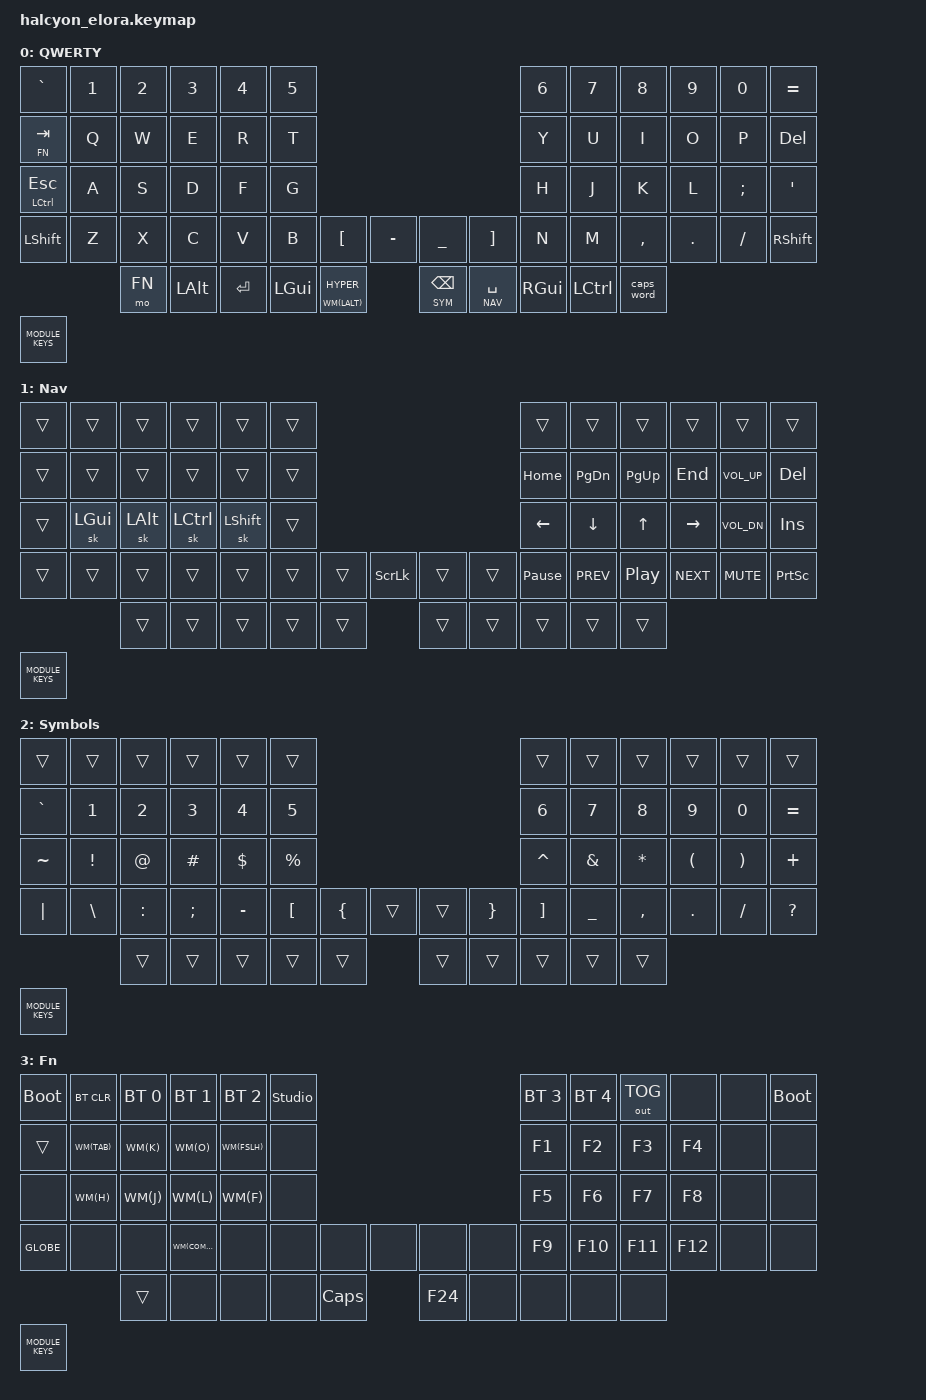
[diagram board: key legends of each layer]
/*
 * Halcyon Elora rev2 (wireless, dongle): Denis's keymap.
 *
 * Positions follow splitkb_halcyon_elora_hlc: rows 0–11, 12–23, 24–35,
 * 36–51 (with the four inner keys), thumbs 52–61, then the ten unused
 * Halcyon module positions 62–71.
 *
 * AeroSpace uses Ctrl+Alt as its modifier, so holding the Hyper thumb or
 * using the Fn window keys drives it; see ~/.nix/aerospace.nix.
 */

#include <behaviors.dtsi>
#include <dt-bindings/zmk/bt.h>
#include <dt-bindings/zmk/keys.h>
#include <dt-bindings/zmk/outputs.h>

#define BASE 0
#define NAV 1
#define SYM 2
#define FN 3

#define HYPER LS(LC(LA(LGUI)))
#define WM(key) LC(LA(key))

#define MODULE_KEYS &none &none &none &none &none &none &none &none &none &none

/* Tab/Fn, Space/Nav and Backspace/Sym take their hold as soon as another key goes down. */
&lt {
    flavor = "hold-preferred";
    tapping-term-ms = <175>;
    quick-tap-ms = <120>;
};

/* QMK's one-shot mods had no timeout; long enough to reach for the mouse. */
&sk {
    release-after-ms = <3000>;
};

/ {
    behaviors {
        /*
         * Esc/Ctrl only becomes Ctrl with a right-hand, thumb or neutral key
         * (Tab/Fn, [ and ]), matching QMK's chordal hold: a quick same-hand
         * roll stays Esc.
         */
        ctl_esc: ctl_esc {
            compatible = "zmk,behavior-hold-tap";
            #binding-cells = <2>;
            flavor = "hold-preferred";
            tapping-term-ms = <175>;
            quick-tap-ms = <120>;
            bindings = <&kp>, <&kp>;
            hold-trigger-key-positions = <
                6 7 8 9 10 11
                12 18 19 20 21 22 23
                30 31 32 33 34 35
                42 44 45 46 47 48 49 50 51
                52 53 54 55 56 57 58 59 60 61
            >;
        };

        /*
         * Tap: one-shot Hyper for app shortcuts. Hold: Ctrl+Alt for AeroSpace.
         * Hold-preferred so any key pressed while the thumb is down gets
         * Ctrl+Alt. Balanced resolved a fast thumb+key chord as a tap, sending
         * Hyper+key instead; Hyper now needs a clean tap before the next key.
         */
        hyp_wm: hyp_wm {
            compatible = "zmk,behavior-hold-tap";
            #binding-cells = <2>;
            flavor = "hold-preferred";
            tapping-term-ms = <175>;
            bindings = <&kp>, <&sk>;
        };

        /*
         * Tap: one Backspace. Press again within 300 ms of that press and hold:
         * Backspace stays down until release, so the OS repeats it. A later hold
         * is still Symbols. Tab/Fn and Space/Nav keep the 120 ms quick-tap.
         */
        bspc_sym: bspc_sym {
            compatible = "zmk,behavior-hold-tap";
            #binding-cells = <2>;
            flavor = "hold-preferred";
            tapping-term-ms = <175>;
            quick-tap-ms = <300>;
            bindings = <&mo>, <&kp>;
        };
    };

    keymap {
        compatible = "zmk,keymap";

        base_layer {
            display-name = "QWERTY";
            bindings = <
&kp GRAVE        &kp N1 &kp N2 &kp N3 &kp N4 &kp N5                                   &kp N6 &kp N7 &kp N8    &kp N9  &kp N0   &kp EQUAL
&lt FN TAB       &kp Q  &kp W  &kp E  &kp R  &kp T                                    &kp Y  &kp U  &kp I     &kp O   &kp P    &kp DEL
&ctl_esc LCTRL ESC &kp A &kp S &kp D  &kp F  &kp G                                    &kp H  &kp J  &kp K     &kp L   &kp SEMI &kp SQT
&kp LSHFT        &kp Z  &kp X  &kp C  &kp V  &kp B  &kp LBKT &kp MINUS   &kp UNDER &kp RBKT &kp N &kp M &kp COMMA &kp DOT &kp FSLH &kp RSHFT
                 &mo FN &kp LALT &kp RET &kp LGUI &hyp_wm WM(LALT) HYPER   &bspc_sym SYM BSPC &lt NAV SPACE &kp RGUI &kp LCTRL &caps_word
MODULE_KEYS
            >;
        };

        nav_layer {
            display-name = "Nav";
            bindings = <
&trans &trans    &trans    &trans     &trans     &trans                             &trans          &trans    &trans    &trans    &trans       &trans
&trans &trans    &trans    &trans     &trans     &trans                             &kp HOME        &kp PG_DN &kp PG_UP &kp END   &kp C_VOL_UP &kp DEL
&trans &sk LGUI  &sk LALT  &sk LCTRL  &sk LSHFT  &trans                             &kp LEFT        &kp DOWN  &kp UP    &kp RIGHT &kp C_VOL_DN &kp INS
&trans &trans    &trans    &trans     &trans     &trans &trans &kp SLCK   &trans &trans &kp PAUSE_BREAK &kp C_PREV &kp C_PP &kp C_NEXT &kp C_MUTE &kp PSCRN
                 &trans    &trans     &trans     &trans &trans            &trans &trans &trans          &trans    &trans
MODULE_KEYS
            >;
        };

        sym_layer {
            display-name = "Symbols";
            bindings = <
&trans    &trans   &trans    &trans   &trans    &trans                               &trans    &trans    &trans    &trans   &trans   &trans
&kp GRAVE &kp N1   &kp N2    &kp N3   &kp N4    &kp N5                               &kp N6    &kp N7    &kp N8    &kp N9   &kp N0   &kp EQUAL
&kp TILDE &kp EXCL &kp AT    &kp HASH &kp DLLR  &kp PRCNT                            &kp CARET &kp AMPS  &kp STAR  &kp LPAR &kp RPAR &kp PLUS
&kp PIPE  &kp BSLH &kp COLON &kp SEMI &kp MINUS &kp LBKT &kp LBRC &trans   &trans &kp RBRC &kp RBKT &kp UNDER &kp COMMA &kp DOT &kp FSLH &kp QMARK
                   &trans    &trans   &trans    &trans   &trans            &trans &trans   &trans    &trans    &trans
MODULE_KEYS
            >;
        };

        fn_layer {
            display-name = "Fn";
            bindings = <
&bootloader &bt BT_CLR      &bt BT_SEL 0    &bt BT_SEL 1     &bt BT_SEL 2      &studio_unlock               &bt BT_SEL 3 &bt BT_SEL 4 &out OUT_TOG &none   &none &bootloader
&trans      &kp WM(TAB)     &kp WM(K)       &kp WM(O)        &kp WM(FSLH)      &none                        &kp F1       &kp F2       &kp F3       &kp F4  &none &none
&none       &kp WM(H)       &kp WM(J)       &kp WM(L)        &kp WM(F)         &none                        &kp F5       &kp F6       &kp F7       &kp F8  &none &none
&kp GLOBE   &none           &none           &kp WM(COMMA)    &none             &none &none &none   &none &none &kp F9   &kp F10      &kp F11      &kp F12 &none &none
                            &trans          &none            &none             &none &kp CAPS      &kp F24 &none &none &none &none
MODULE_KEYS
            >;
        };
    };
};
